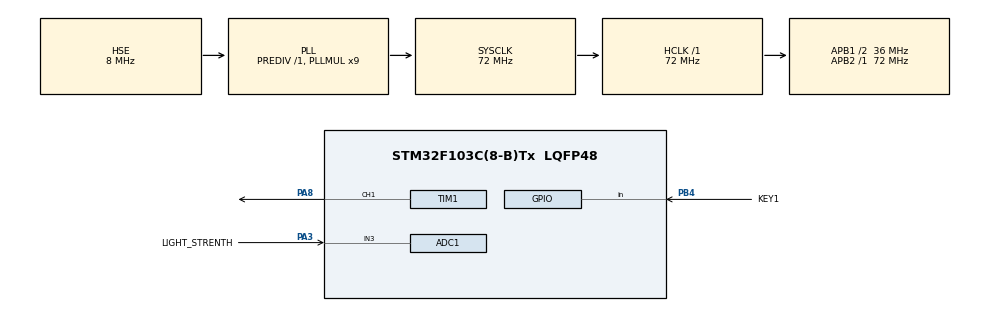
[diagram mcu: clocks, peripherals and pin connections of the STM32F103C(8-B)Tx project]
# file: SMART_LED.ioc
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ADC1.Channel-0\#ChannelRegularConversion=ADC_CHANNEL_3
ADC1.ContinuousConvMode=ENABLE
ADC1.NbrOfConversion=1
ADC1.NbrOfConversionFlag=1
ADC1.Rank-0\#ChannelRegularConversion=1
ADC1.SamplingTime-0\#ChannelRegularConversion=ADC_SAMPLETIME_1CYCLE_5
ADC1.master=1
Mcu.Family=STM32F1
Mcu.Name=STM32F103C(8-B)Tx
Mcu.Package=LQFP48
NVIC.PriorityGroup=NVIC_PRIORITYGROUP_4
PA13.Mode=Serial_Wire
PA13.Signal=SYS_JTMS-SWDIO
PA14.Mode=Serial_Wire
PA14.Signal=SYS_JTCK-SWCLK
PA3.GPIO_Label=LIGHT_STRENTH
PA3.Signal=ADCx_IN3
PA8.Signal=S_TIM1_CH1
PB4.GPIO_Label=KEY1
PB4.GPIO_PuPd=GPIO_PULLUP
PB4.Signal=GPIO_Input
PD0-OSC_IN.Mode=HSE-External-Oscillator
PD0-OSC_IN.Signal=RCC_OSC_IN
PD1-OSC_OUT.Mode=HSE-External-Oscillator
PD1-OSC_OUT.Signal=RCC_OSC_OUT
ProjectManager.HeapSize=0x200
ProjectManager.StackSize=0x400
ProjectManager.TargetToolchain=STM32CubeIDE
RCC.ADCPresc=RCC_ADCPCLK2_DIV6
RCC.AHBFreq_Value=72000000
RCC.APB1CLKDivider=RCC_HCLK_DIV2
RCC.APB1Freq_Value=36000000
RCC.APB1TimFreq_Value=72000000
RCC.APB2Freq_Value=72000000
RCC.APB2TimFreq_Value=72000000
RCC.HCLKFreq_Value=72000000
RCC.PLLMUL=RCC_PLL_MUL9
RCC.PLLSourceVirtual=RCC_PLLSOURCE_HSE
RCC.SYSCLKFreq_VALUE=72000000
RCC.SYSCLKSource=RCC_SYSCLKSOURCE_PLLCLK
RCC.USBFreq_Value=72000000
SH.ADCx_IN3.0=ADC1_IN3,IN3
SH.S_TIM1_CH1.0=TIM1_CH1,PWM Generation1 CH1
TIM1.Channel-PWM\ Generation1\ CH1=TIM_CHANNEL_1
TIM1.Period=19999
TIM1.Prescaler=3
VP_TIM1_VS_ClockSourceINT.Mode=Internal
board=custom

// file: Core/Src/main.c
/* USER CODE BEGIN Header */
/**
  ******************************************************************************
  * @file           : main.c
  * @brief          : Main program body
  ******************************************************************************
  * @attention
  *
  * Copyright (c) 2026 STMicroelectronics.
  * All rights reserved.
  *
  * This software is licensed under terms that can be found in the LICENSE file
  * in the root directory of this software component.
  * If no LICENSE file comes with this software, it is provided AS-IS.
  *
  ******************************************************************************
  */
/* USER CODE END Header */
#include "main.h"
#include "adc.h"
#include "tim.h"
#include "gpio.h"

/* USER CODE BEGIN Includes */
#include "key.h"
#include "oled_mode.h"
/* USER CODE END Includes */

/* USER CODE BEGIN PD */
/* LED thresholds and level definitions moved to Core/Inc/oled_mode.h */
/* USER CODE END PD */

/* USER CODE BEGIN PV */
/* mode and level variables moved to oled_mode.c */
/* USER CODE END PV */

void SystemClock_Config(void);

/* USER CODE BEGIN 0 */
/* LED control moved to oled_mode.c */

/* USER CODE END 0 */

int main(void)
{

  /* MCU Configuration--------------------------------------------------------*/

  /* Reset of all peripherals, Initializes the Flash interface and the Systick. */
  HAL_Init();

  /* Configure the system clock */
  SystemClock_Config();

  /* Initialize all configured peripherals */
  MX_GPIO_Init();
  MX_ADC1_Init();
  MX_TIM1_Init();

  /* Infinite loop */
  /* USER CODE BEGIN WHILE */
  HAL_TIM_Base_Start(&htim1);
  HAL_TIM_PWM_Start(&htim1,TIM_CHANNEL_1);
  HAL_ADC_Start(&hadc1);
    // 初始手动模式，LED关闭
    manual_level = 0;
    Set_LED_Level(manual_level);
    current_mode = 0; // 手动
  while (1)
  {
    // 1. 按键扫描（建议每10ms调用一次，可放在定时器中断或主循环加延时）
        KEY_Scan();

        // 2. 处理短按
        if(KEY_GetShortPress()) {
            if(current_mode == 0) { // 手动模式下
                // 挡位循环：0->1->2->3->0
                manual_level = (manual_level + 1) % 4;
                Set_LED_Level(manual_level);
            } else {
                // 自动模式下，短按无效
            }
        }

        // 3. 处理长按（模式切换）
        if(KEY_GetLongPress()) {
            if(current_mode == 0) { // 手动 -> 自动
                current_mode = 1;
                // 立即读取光照并设置
                auto_level = Get_LightLevel();
                Set_LED_Level(auto_level);
            } else { // 自动 -> 手动
                current_mode = 0;
                // 恢复到之前手动设定的挡位
                Set_LED_Level(manual_level);
            }
        }

        // 4. 自动模式下，周期性更新光照（每隔100ms读取一次）
        if(current_mode == 1) {
            static uint32_t last_read = 0;
            if(HAL_GetTick() - last_read >= 100) {
                last_read = HAL_GetTick();
                auto_level = Get_LightLevel();
                Set_LED_Level(auto_level);
            }
        }

        HAL_Delay(10); // 主循环周期10ms，配合按键扫描
    /* USER CODE END WHILE */

  }
}

void SystemClock_Config(void)
{
  RCC_OscInitTypeDef RCC_OscInitStruct = {0};
  RCC_ClkInitTypeDef RCC_ClkInitStruct = {0};
  RCC_PeriphCLKInitTypeDef PeriphClkInit = {0};

  /** Initializes the RCC Oscillators according to the specified parameters
  * in the RCC_OscInitTypeDef structure.
  */
  RCC_OscInitStruct.OscillatorType = RCC_OSCILLATORTYPE_HSE;
  RCC_OscInitStruct.HSEState = RCC_HSE_ON;
  RCC_OscInitStruct.HSEPredivValue = RCC_HSE_PREDIV_DIV1;
  RCC_OscInitStruct.HSIState = RCC_HSI_ON;
  RCC_OscInitStruct.PLL.PLLState = RCC_PLL_ON;
  RCC_OscInitStruct.PLL.PLLSource = RCC_PLLSOURCE_HSE;
  RCC_OscInitStruct.PLL.PLLMUL = RCC_PLL_MUL9;
  if (HAL_RCC_OscConfig(&RCC_OscInitStruct) != HAL_OK)
  {
    Error_Handler();
  }

  /** Initializes the CPU, AHB and APB buses clocks
  */
  RCC_ClkInitStruct.ClockType = RCC_CLOCKTYPE_HCLK|RCC_CLOCKTYPE_SYSCLK
                              |RCC_CLOCKTYPE_PCLK1|RCC_CLOCKTYPE_PCLK2;
  RCC_ClkInitStruct.SYSCLKSource = RCC_SYSCLKSOURCE_PLLCLK;
  RCC_ClkInitStruct.AHBCLKDivider = RCC_SYSCLK_DIV1;
  RCC_ClkInitStruct.APB1CLKDivider = RCC_HCLK_DIV2;
  RCC_ClkInitStruct.APB2CLKDivider = RCC_HCLK_DIV1;

  if (HAL_RCC_ClockConfig(&RCC_ClkInitStruct, FLASH_LATENCY_2) != HAL_OK)
  {
    Error_Handler();
  }
  PeriphClkInit.PeriphClockSelection = RCC_PERIPHCLK_ADC;
  PeriphClkInit.AdcClockSelection = RCC_ADCPCLK2_DIV6;
  if (HAL_RCCEx_PeriphCLKConfig(&PeriphClkInit) != HAL_OK)
  {
    Error_Handler();
  }
}

void Error_Handler(void)
{
  __disable_irq();
  while (1)
  {
  }
}
